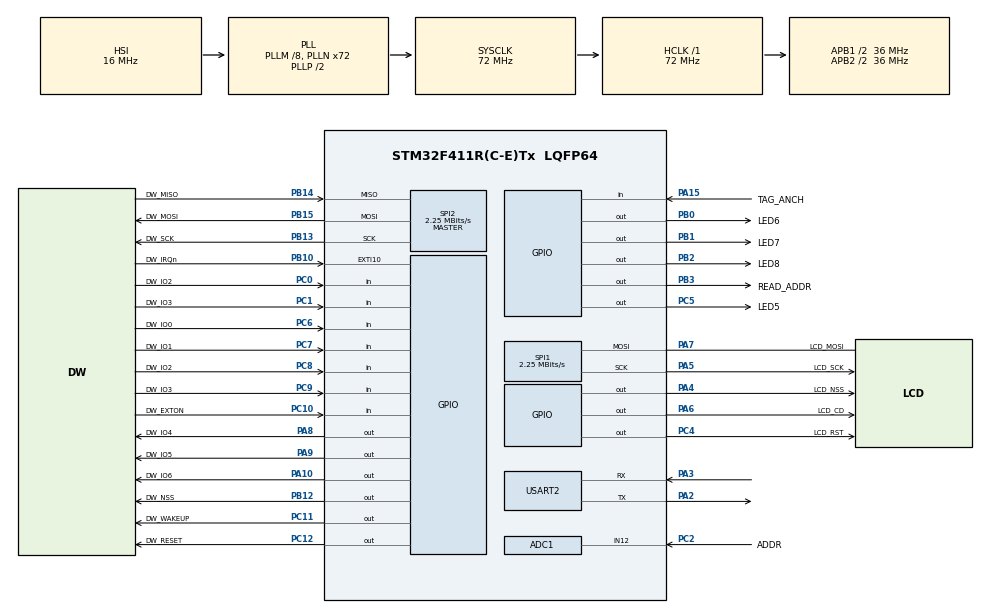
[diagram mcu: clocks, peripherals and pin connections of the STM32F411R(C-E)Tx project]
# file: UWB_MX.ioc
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ADC1.Channel-4\#ChannelRegularConversion=ADC_CHANNEL_12
ADC1.NbrOfConversionFlag=1
ADC1.Rank-4\#ChannelRegularConversion=1
ADC1.SamplingTime-4\#ChannelRegularConversion=ADC_SAMPLETIME_3CYCLES
ADC1.master=1
Mcu.Family=STM32F4
Mcu.Name=STM32F411R(C-E)Tx
Mcu.Package=LQFP64
NVIC.EXTI15_10_IRQn=true\:1\:0\:true\:false\:true
NVIC.PriorityGroup=NVIC_PRIORITYGROUP_4
PA10.GPIO_Label=DW_IO6
PA10.Signal=GPIO_Output
PA13.Mode=Serial_Wire
PA13.Signal=SYS_JTMS-SWDIO
PA14.Mode=Serial_Wire
PA14.Signal=SYS_JTCK-SWCLK
PA15.GPIO_Label=TAG_ANCH
PA15.Signal=GPIO_Input
PA2.Mode=Asynchronous
PA2.Signal=USART2_TX
PA3.Mode=Asynchronous
PA3.Signal=USART2_RX
PA4.GPIO_Label=LCD_NSS
PA4.Signal=GPIO_Output
PA5.GPIO_Label=LCD_SCK
PA5.Mode=Simplex_Bidirectional_Master
PA5.Signal=SPI1_SCK
PA6.GPIO_Label=LCD_CD
PA6.Signal=GPIO_Output
PA7.GPIO_Label=LCD_MOSI
PA7.Mode=Simplex_Bidirectional_Master
PA7.Signal=SPI1_MOSI
PA8.GPIO_Label=DW_IO4
PA8.Signal=GPIO_Output
PA9.GPIO_Label=DW_IO5
PA9.Signal=GPIO_Output
PB0.GPIO_Label=LED6
PB0.Signal=GPIO_Output
PB1.GPIO_Label=LED7
PB1.Signal=GPIO_Output
PB10.GPIO_Label=DW_IRQn
PB10.Signal=GPXTI10
PB12.GPIO_Label=DW_NSS
PB12.Signal=GPIO_Output
PB13.GPIO_Label=DW_SCK
PB13.Mode=Full_Duplex_Master
PB13.Signal=SPI2_SCK
PB14.GPIO_Label=DW_MISO
PB14.Mode=Full_Duplex_Master
PB14.Signal=SPI2_MISO
PB15.GPIO_Label=DW_MOSI
PB15.Mode=Full_Duplex_Master
PB15.Signal=SPI2_MOSI
PB2.GPIO_Label=LED8
PB2.Signal=GPIO_Output
PB3.GPIO_Label=READ_ADDR
PB3.Signal=GPIO_Output
PC0.GPIO_Label=DW_IO2
PC0.Signal=GPIO_Input
PC1.GPIO_Label=DW_IO3
PC1.Signal=GPIO_Input
PC10.GPIO_Label=DW_EXTON
PC10.Signal=GPIO_Input
PC11.GPIO_Label=DW_WAKEUP
PC11.Signal=GPIO_Output
PC12.GPIO_Label=DW_RESET
PC12.Signal=GPIO_Output
PC2.GPIO_Label=ADDR
PC2.Signal=ADCx_IN12
PC4.GPIO_Label=LCD_RST
PC4.Signal=GPIO_Output
PC5.GPIO_Label=LED5
PC5.Signal=GPIO_Output
PC6.GPIO_Label=DW_IO0
PC6.Signal=GPIO_Input
PC7.GPIO_Label=DW_IO1
PC7.Signal=GPIO_Input
PC8.GPIO_Label=DW_IO2
PC8.Signal=GPIO_Input
PC9.GPIO_Label=DW_IO3
PC9.Signal=GPIO_Input
ProjectManager.HeapSize=0x200
ProjectManager.StackSize=0x400
ProjectManager.TargetToolchain=SW4STM32
RCC.48MHZClocksFreq_Value=48000000
RCC.AHBFreq_Value=72000000
RCC.APB1CLKDivider=RCC_HCLK_DIV2
RCC.APB1Freq_Value=36000000
RCC.APB1TimFreq_Value=72000000
RCC.APB2CLKDivider=RCC_HCLK_DIV2
RCC.APB2Freq_Value=36000000
RCC.APB2TimFreq_Value=72000000
RCC.CortexFreq_Value=72000000
RCC.HCLKFreq_Value=72000000
RCC.HSE_VALUE=12000000
RCC.HSI_VALUE=16000000
RCC.LSE_VALUE=32768
RCC.PLLM=8
RCC.PLLN=72
RCC.PLLQ=3
RCC.RCC_RTC_Clock_Source=RCC_RTCCLKSOURCE_LSI
RCC.RCC_RTC_Clock_SourceVirtual=RCC_RTCCLKSOURCE_LSE
RCC.SYSCLKFreq_VALUE=72000000
RCC.SYSCLKSource=RCC_SYSCLKSOURCE_PLLCLK
RCC.VCOOutputFreq_Value=144000000
SH.ADCx_IN12.0=ADC1_IN12,IN12
SPI1.BaudRatePrescaler=SPI_BAUDRATEPRESCALER_16
SPI1.CalculateBaudRate=2.25 MBits/s
SPI1.Direction=SPI_DIRECTION_1LINE
SPI1.Mode=SPI_MODE_MASTER
SPI1.VirtualType=VM_MASTER
SPI2.BaudRatePrescaler=SPI_BAUDRATEPRESCALER_16
SPI2.CalculateBaudRate=2.25 MBits/s
SPI2.Direction=SPI_DIRECTION_2LINES
SPI2.Mode=SPI_MODE_MASTER
SPI2.VirtualType=VM_MASTER
USART2.VirtualMode=VM_ASYNC
board=UWB_MX

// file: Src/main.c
/**
  ******************************************************************************
  * File Name          : main.c
  * Description        : Main program body
  ******************************************************************************
  ** This notice applies to any and all portions of this file
  * that are not between comment pairs USER CODE BEGIN and
  * USER CODE END. Other portions of this file, whether
  * inserted by the user or by software development tools
  * are owned by their respective copyright owners.
  *
  * COPYRIGHT(c) 2017 STMicroelectronics
  *
  * Redistribution and use in source and binary forms, with or without modification,
  * are permitted provided that the following conditions are met:
  *   1. Redistributions of source code must retain the above copyright notice,
  *      this list of conditions and the following disclaimer.
  *   2. Redistributions in binary form must reproduce the above copyright notice,
  *      this list of conditions and the following disclaimer in the documentation
  *      and/or other materials provided with the distribution.
  *   3. Neither the name of STMicroelectronics nor the names of its contributors
  *      may be used to endorse or promote products derived from this software
  *      without specific prior written permission.
  *
  * THIS SOFTWARE IS PROVIDED BY THE COPYRIGHT HOLDERS AND CONTRIBUTORS "AS IS"
  * AND ANY EXPRESS OR IMPLIED WARRANTIES, INCLUDING, BUT NOT LIMITED TO, THE
  * IMPLIED WARRANTIES OF MERCHANTABILITY AND FITNESS FOR A PARTICULAR PURPOSE ARE
  * DISCLAIMED. IN NO EVENT SHALL THE COPYRIGHT HOLDER OR CONTRIBUTORS BE LIABLE
  * FOR ANY DIRECT, INDIRECT, INCIDENTAL, SPECIAL, EXEMPLARY, OR CONSEQUENTIAL
  * DAMAGES (INCLUDING, BUT NOT LIMITED TO, PROCUREMENT OF SUBSTITUTE GOODS OR
  * SERVICES; LOSS OF USE, DATA, OR PROFITS; OR BUSINESS INTERRUPTION) HOWEVER
  * CAUSED AND ON ANY THEORY OF LIABILITY, WHETHER IN CONTRACT, STRICT LIABILITY,
  * OR TORT (INCLUDING NEGLIGENCE OR OTHERWISE) ARISING IN ANY WAY OUT OF THE USE
  * OF THIS SOFTWARE, EVEN IF ADVISED OF THE POSSIBILITY OF SUCH DAMAGE.
  *
  ******************************************************************************
  */
#include "main.h"
#include "stm32f4xx_hal.h"

/* USER CODE BEGIN Includes */
/*! ----------------------------------------------------------------------------
 *  @file    main.c
 *  @brief   wrapper for main DecaRanging application
 *			 the main.c is generated using CubeMx tool
 *           which initialize all peripherals of MCU
 *           and then is calling to dw_main().
 * @attention
 *
 * Copyright 2016 (c) DecaWave Ltd, Dublin, Ireland.
 *
 * All rights reserved.
 *
 * @author DecaWave
 */
#include "port.h"

app_t 	app;
/* USER CODE END Includes */

ADC_HandleTypeDef hadc1;

SPI_HandleTypeDef hspi1;
SPI_HandleTypeDef hspi2;

UART_HandleTypeDef huart2;

/* USER CODE BEGIN PV */
/* Private variables ---------------------------------------------------------*/

/* USER CODE END PV */

void SystemClock_Config(void);
static void MX_GPIO_Init(void);
static void MX_ADC1_Init(void);
static void MX_SPI1_Init(void);
static void MX_SPI2_Init(void);
static void MX_USART2_UART_Init(void);

/* USER CODE BEGIN PFP */
/* Private function prototypes -----------------------------------------------*/

/* USER CODE END PFP */

/* USER CODE BEGIN 0 */
extern void dw_main(void);
/* USER CODE END 0 */

int main(void)
{

  /* MCU Configuration----------------------------------------------------------*/

  /* Reset of all peripherals, Initializes the Flash interface and the Systick. */
  HAL_Init();

  /* Configure the system clock */
  SystemClock_Config();

  /* Initialize all configured peripherals */
  MX_GPIO_Init();
  MX_ADC1_Init();
  MX_SPI1_Init();
  MX_SPI2_Init();
  MX_USART2_UART_Init();

  /* USER CODE BEGIN 2 */

  /*
   * DW_RESET_Pin has been configured by CubeMx as Exti0 line
   * Reconfigure the line as Input
   */
  setup_DW1000RSTnIRQ(0);
  dw_main();
  /* USER CODE END 2 */

  /* Infinite loop */
  while (1)
  {

  /* USER CODE BEGIN 3 */
	  HAL_GPIO_TogglePin(LED5_GPIO_Port, LED5_Pin);
	  HAL_GPIO_TogglePin(LED6_GPIO_Port, LED6_Pin);
	  HAL_GPIO_TogglePin(LED7_GPIO_Port, LED7_Pin);
	  HAL_GPIO_TogglePin(LED8_GPIO_Port, LED8_Pin);
	  HAL_Delay(500);

  }
  /* USER CODE END 3 */

}

/** System Clock Configuration
*/
void SystemClock_Config(void)
{

  RCC_OscInitTypeDef RCC_OscInitStruct;
  RCC_ClkInitTypeDef RCC_ClkInitStruct;

    /**Configure the main internal regulator output voltage
    */
  __HAL_RCC_PWR_CLK_ENABLE();

  __HAL_PWR_VOLTAGESCALING_CONFIG(PWR_REGULATOR_VOLTAGE_SCALE1);

    /**Initializes the CPU, AHB and APB busses clocks
    */
  RCC_OscInitStruct.OscillatorType = RCC_OSCILLATORTYPE_HSI;
  RCC_OscInitStruct.HSIState = RCC_HSI_ON;
  RCC_OscInitStruct.HSICalibrationValue = 16;
  RCC_OscInitStruct.PLL.PLLState = RCC_PLL_ON;
  RCC_OscInitStruct.PLL.PLLSource = RCC_PLLSOURCE_HSI;
  RCC_OscInitStruct.PLL.PLLM = 8;
  RCC_OscInitStruct.PLL.PLLN = 72;
  RCC_OscInitStruct.PLL.PLLP = RCC_PLLP_DIV2;
  RCC_OscInitStruct.PLL.PLLQ = 3;
  if (HAL_RCC_OscConfig(&RCC_OscInitStruct) != HAL_OK)
  {
    _Error_Handler(__FILE__, __LINE__);
  }

    /**Initializes the CPU, AHB and APB busses clocks
    */
  RCC_ClkInitStruct.ClockType = RCC_CLOCKTYPE_HCLK|RCC_CLOCKTYPE_SYSCLK
                              |RCC_CLOCKTYPE_PCLK1|RCC_CLOCKTYPE_PCLK2;
  RCC_ClkInitStruct.SYSCLKSource = RCC_SYSCLKSOURCE_PLLCLK;
  RCC_ClkInitStruct.AHBCLKDivider = RCC_SYSCLK_DIV1;
  RCC_ClkInitStruct.APB1CLKDivider = RCC_HCLK_DIV2;
  RCC_ClkInitStruct.APB2CLKDivider = RCC_HCLK_DIV2;

  if (HAL_RCC_ClockConfig(&RCC_ClkInitStruct, FLASH_LATENCY_2) != HAL_OK)
  {
    _Error_Handler(__FILE__, __LINE__);
  }

    /**Configure the Systick interrupt time
    */
  HAL_SYSTICK_Config(HAL_RCC_GetHCLKFreq()/1000);

    /**Configure the Systick
    */
  HAL_SYSTICK_CLKSourceConfig(SYSTICK_CLKSOURCE_HCLK);

  /* SysTick_IRQn interrupt configuration */
  HAL_NVIC_SetPriority(SysTick_IRQn, 0, 0);
}

/* ADC1 init function */
static void MX_ADC1_Init(void)
{

  ADC_ChannelConfTypeDef sConfig;

    /**Configure the global features of the ADC (Clock, Resolution, Data Alignment and number of conversion)
    */
  hadc1.Instance = ADC1;
  hadc1.Init.ClockPrescaler = ADC_CLOCK_SYNC_PCLK_DIV2;
  hadc1.Init.Resolution = ADC_RESOLUTION_12B;
  hadc1.Init.ScanConvMode = DISABLE;
  hadc1.Init.ContinuousConvMode = DISABLE;
  hadc1.Init.DiscontinuousConvMode = DISABLE;
  hadc1.Init.ExternalTrigConvEdge = ADC_EXTERNALTRIGCONVEDGE_NONE;
  hadc1.Init.ExternalTrigConv = ADC_SOFTWARE_START;
  hadc1.Init.DataAlign = ADC_DATAALIGN_RIGHT;
  hadc1.Init.NbrOfConversion = 1;
  hadc1.Init.DMAContinuousRequests = DISABLE;
  hadc1.Init.EOCSelection = ADC_EOC_SINGLE_CONV;
  if (HAL_ADC_Init(&hadc1) != HAL_OK)
  {
    _Error_Handler(__FILE__, __LINE__);
  }

    /**Configure for the selected ADC regular channel its corresponding rank in the sequencer and its sample time.
    */
  sConfig.Channel = ADC_CHANNEL_12;
  sConfig.Rank = 1;
  sConfig.SamplingTime = ADC_SAMPLETIME_3CYCLES;
  if (HAL_ADC_ConfigChannel(&hadc1, &sConfig) != HAL_OK)
  {
    _Error_Handler(__FILE__, __LINE__);
  }

}

/* SPI1 init function */
static void MX_SPI1_Init(void)
{

  hspi1.Instance = SPI1;
  hspi1.Init.Mode = SPI_MODE_MASTER;
  hspi1.Init.Direction = SPI_DIRECTION_1LINE;
  hspi1.Init.DataSize = SPI_DATASIZE_8BIT;
  hspi1.Init.CLKPolarity = SPI_POLARITY_LOW;
  hspi1.Init.CLKPhase = SPI_PHASE_1EDGE;
  hspi1.Init.NSS = SPI_NSS_SOFT;
  hspi1.Init.BaudRatePrescaler = SPI_BAUDRATEPRESCALER_16;
  hspi1.Init.FirstBit = SPI_FIRSTBIT_MSB;
  hspi1.Init.TIMode = SPI_TIMODE_DISABLE;
  hspi1.Init.CRCCalculation = SPI_CRCCALCULATION_DISABLE;
  hspi1.Init.CRCPolynomial = 10;
  if (HAL_SPI_Init(&hspi1) != HAL_OK)
  {
    _Error_Handler(__FILE__, __LINE__);
  }

}

/* SPI2 init function */
static void MX_SPI2_Init(void)
{

  hspi2.Instance = SPI2;
  hspi2.Init.Mode = SPI_MODE_MASTER;
  hspi2.Init.Direction = SPI_DIRECTION_2LINES;
  hspi2.Init.DataSize = SPI_DATASIZE_8BIT;
  hspi2.Init.CLKPolarity = SPI_POLARITY_LOW;
  hspi2.Init.CLKPhase = SPI_PHASE_1EDGE;
  hspi2.Init.NSS = SPI_NSS_SOFT;
  hspi2.Init.BaudRatePrescaler = SPI_BAUDRATEPRESCALER_16;
  hspi2.Init.FirstBit = SPI_FIRSTBIT_MSB;
  hspi2.Init.TIMode = SPI_TIMODE_DISABLE;
  hspi2.Init.CRCCalculation = SPI_CRCCALCULATION_DISABLE;
  hspi2.Init.CRCPolynomial = 10;
  if (HAL_SPI_Init(&hspi2) != HAL_OK)
  {
    _Error_Handler(__FILE__, __LINE__);
  }

}

/* USART2 init function */
static void MX_USART2_UART_Init(void)
{

  huart2.Instance = USART2;
  huart2.Init.BaudRate = 115200;
  huart2.Init.WordLength = UART_WORDLENGTH_8B;
  huart2.Init.StopBits = UART_STOPBITS_1;
  huart2.Init.Parity = UART_PARITY_NONE;
  huart2.Init.Mode = UART_MODE_TX_RX;
  huart2.Init.HwFlowCtl = UART_HWCONTROL_NONE;
  huart2.Init.OverSampling = UART_OVERSAMPLING_16;
  if (HAL_UART_Init(&huart2) != HAL_OK)
  {
    _Error_Handler(__FILE__, __LINE__);
  }

}

/** Configure pins as
        * Analog
        * Input
        * Output
        * EVENT_OUT
        * EXTI
*/
static void MX_GPIO_Init(void)
{

  GPIO_InitTypeDef GPIO_InitStruct;

  /* GPIO Ports Clock Enable */
  __HAL_RCC_GPIOC_CLK_ENABLE();
  __HAL_RCC_GPIOA_CLK_ENABLE();
  __HAL_RCC_GPIOB_CLK_ENABLE();

  /*Configure GPIO pin Output Level */
  HAL_GPIO_WritePin(GPIOA, LCD_NSS_Pin|LCD_CD_Pin|DW_IO4_Pin|DW_IO5_Pin
                          |DW_IO6_Pin, GPIO_PIN_RESET);

  /*Configure GPIO pin Output Level */
  HAL_GPIO_WritePin(GPIOC, LCD_RST_Pin|LED5_Pin|DW_WAKEUP_Pin|DW_RESET_Pin, GPIO_PIN_RESET);

  /*Configure GPIO pin Output Level */
  HAL_GPIO_WritePin(GPIOB, LED6_Pin|LED7_Pin|LED8_Pin|DW_NSS_Pin
                          |READ_ADDR_Pin, GPIO_PIN_RESET);

  /*Configure GPIO pins : DW_IO2_Pin DW_IO3_Pin DW_IO0_Pin DW_IO1_Pin
                           DW_IO2C8_Pin DW_IO3C9_Pin DW_EXTON_Pin */
  GPIO_InitStruct.Pin = DW_IO2_Pin|DW_IO3_Pin|DW_IO0_Pin|DW_IO1_Pin
                          |DW_IO2C8_Pin|DW_IO3C9_Pin|DW_EXTON_Pin;
  GPIO_InitStruct.Mode = GPIO_MODE_INPUT;
  GPIO_InitStruct.Pull = GPIO_NOPULL;
  HAL_GPIO_Init(GPIOC, &GPIO_InitStruct);

  /*Configure GPIO pins : LCD_NSS_Pin LCD_CD_Pin DW_IO4_Pin DW_IO5_Pin
                           DW_IO6_Pin */
  GPIO_InitStruct.Pin = LCD_NSS_Pin|LCD_CD_Pin|DW_IO4_Pin|DW_IO5_Pin
                          |DW_IO6_Pin;
  GPIO_InitStruct.Mode = GPIO_MODE_OUTPUT_PP;
  GPIO_InitStruct.Pull = GPIO_NOPULL;
  GPIO_InitStruct.Speed = GPIO_SPEED_FREQ_LOW;
  HAL_GPIO_Init(GPIOA, &GPIO_InitStruct);

  /*Configure GPIO pins : LCD_RST_Pin LED5_Pin DW_WAKEUP_Pin DW_RESET_Pin */
  GPIO_InitStruct.Pin = LCD_RST_Pin|LED5_Pin|DW_WAKEUP_Pin|DW_RESET_Pin;
  GPIO_InitStruct.Mode = GPIO_MODE_OUTPUT_PP;
  GPIO_InitStruct.Pull = GPIO_NOPULL;
  GPIO_InitStruct.Speed = GPIO_SPEED_FREQ_LOW;
  HAL_GPIO_Init(GPIOC, &GPIO_InitStruct);

  /*Configure GPIO pins : LED6_Pin LED7_Pin LED8_Pin DW_NSS_Pin
                           READ_ADDR_Pin */
  GPIO_InitStruct.Pin = LED6_Pin|LED7_Pin|LED8_Pin|DW_NSS_Pin
                          |READ_ADDR_Pin;
  GPIO_InitStruct.Mode = GPIO_MODE_OUTPUT_PP;
  GPIO_InitStruct.Pull = GPIO_NOPULL;
  GPIO_InitStruct.Speed = GPIO_SPEED_FREQ_LOW;
  HAL_GPIO_Init(GPIOB, &GPIO_InitStruct);

  /*Configure GPIO pin : DW_IRQn_Pin */
  GPIO_InitStruct.Pin = DW_IRQn_Pin;
  GPIO_InitStruct.Mode = GPIO_MODE_IT_RISING;
  GPIO_InitStruct.Pull = GPIO_NOPULL;
  HAL_GPIO_Init(DW_IRQn_GPIO_Port, &GPIO_InitStruct);

  /*Configure GPIO pin : TAG_ANCH_Pin */
  GPIO_InitStruct.Pin = TAG_ANCH_Pin;
  GPIO_InitStruct.Mode = GPIO_MODE_INPUT;
  GPIO_InitStruct.Pull = GPIO_NOPULL;
  HAL_GPIO_Init(TAG_ANCH_GPIO_Port, &GPIO_InitStruct);

  /* EXTI interrupt init*/
  HAL_NVIC_SetPriority(EXTI15_10_IRQn, 1, 0);
  HAL_NVIC_EnableIRQ(EXTI15_10_IRQn);

}

void _Error_Handler(char * file, int line)
{
  while(1)
  {
  }
}

/************************ (C) COPYRIGHT STMicroelectronics *****END OF FILE****/
